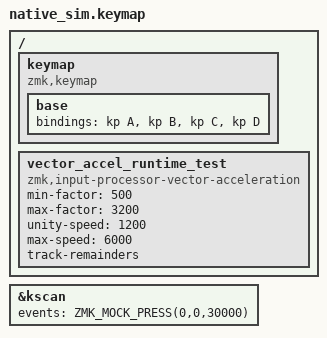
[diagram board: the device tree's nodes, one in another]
/*
 * Copyright (c) 2026 amgskobo
 * SPDX-License-Identifier: MIT
 */

#include <behaviors.dtsi>
#include <dt-bindings/zmk/keys.h>
#include <dt-bindings/zmk/kscan_mock.h>

/ {
    keymap {
        compatible = "zmk,keymap";

        base {
            bindings = <&kp A &kp B &kp C &kp D>;
        };
    };

    vector_accel_runtime_test: vector_accel_runtime_test {
        compatible = "zmk,input-processor-vector-acceleration";
        #input-processor-cells = <0>;
        min-factor = <500>;
        max-factor = <3200>;
        unity-speed = <1200>;
        max-speed = <6000>;
        track-remainders;
    };
};

&kscan {
    events = <ZMK_MOCK_PRESS(0,0,30000)>;
};
